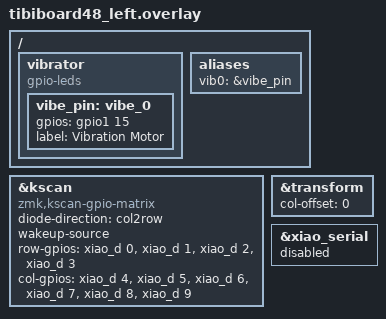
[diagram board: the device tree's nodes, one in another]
#include "tibiboard48.dtsi"

&kscan {
    compatible = "zmk,kscan-gpio-matrix";
    diode-direction = "col2row";
    wakeup-source;

    row-gpios
        = <&xiao_d 0 (GPIO_ACTIVE_HIGH | GPIO_PULL_DOWN)>
        , <&xiao_d 1 (GPIO_ACTIVE_HIGH | GPIO_PULL_DOWN)>
        , <&xiao_d 2 (GPIO_ACTIVE_HIGH | GPIO_PULL_DOWN)>
        , <&xiao_d 3 (GPIO_ACTIVE_HIGH | GPIO_PULL_DOWN)>
        ;

    col-gpios
        = <&xiao_d 4 GPIO_ACTIVE_HIGH>
        , <&xiao_d 5 GPIO_ACTIVE_HIGH>
        , <&xiao_d 6 GPIO_ACTIVE_HIGH> // ← ここがTXピン
        , <&xiao_d 7 GPIO_ACTIVE_HIGH> // ← ここがRXピン
        , <&xiao_d 8 GPIO_ACTIVE_HIGH>
        , <&xiao_d 9 GPIO_ACTIVE_HIGH>
        ;
};

&transform {
    col-offset = <0>;
};

/ {
    vibrator: vibrator {
        compatible = "gpio-leds";
        vibe_pin: vibe_0 {
            gpios = <&gpio1 15 (GPIO_ACTIVE_HIGH | GPIO_PULL_DOWN)>;
            label = "Vibration Motor";
        };
    };

    aliases {
        vib0 = &vibe_pin;
    };
};

/* --- ここから追記：シリアルピンをキー入力用に解放する --- */
&xiao_serial {
    status = "disabled";
};
